AUTOSAR XML (schema 4-0-3)
standard types defined: Boolean, UInt32, UInt8
package /AUTOSAR_Platform/DataConstrs
  range DC_Boolean: raw 0..1
  range DC_UInt8: raw 0..255
package /PATAC/MSM/ComponentTypes
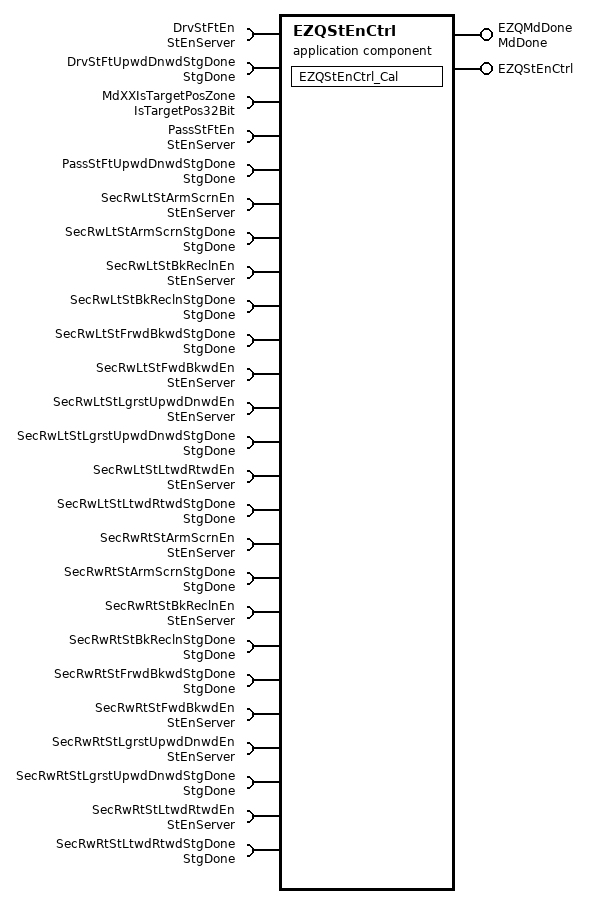
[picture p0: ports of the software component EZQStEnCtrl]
  application sw component type EZQStEnCtrl
    provide port EZQMdDone: nonqueued-sender-com-spec{data-element=MdDone/Val, init-value=0}, provided-interface=MdDone
    provide port EZQStEnCtrl: server-com-spec{operation=Cal, queue-length=1}, provided-interface=EZQStEnCtrl
    25 x require port:
      DrvStFtEn: required-com-specs=[Clear, Get, Set], required-interface=StEnServer
      DrvStFtUpwdDnwdStgDone: nonqueued-receiver-com-spec{data-element=StgDone/Val, filter=data-filter-type=ALWAYS, init-value=0}, required-interface=StgDone
      MdXXIsTargetPosZone: nonqueued-receiver-com-spec{data-element=IsTargetPos32Bit/Val, filter=data-filter-type=ALWAYS, init-value=0}, required-interface=IsTargetPos32Bit
      PassStFtEn: required-com-specs=[Clear, Get, Set], required-interface=StEnServer
      PassStFtUpwdDnwdStgDone: nonqueued-receiver-com-spec{data-element=StgDone/Val, filter=data-filter-type=ALWAYS, init-value=0}, required-interface=StgDone
      SecRwLtStArmScrnEn: required-com-specs=[Clear, Get, Set], required-interface=StEnServer
      SecRwLtStArmScrnStgDone: nonqueued-receiver-com-spec{data-element=StgDone/Val, filter=data-filter-type=ALWAYS, init-value=0}, required-interface=StgDone
      SecRwLtStBkReclnEn: required-com-specs=[Clear, Get, Set], required-interface=StEnServer
      SecRwLtStBkReclnStgDone: nonqueued-receiver-com-spec{data-element=StgDone/Val, filter=data-filter-type=ALWAYS, init-value=0}, required-interface=StgDone
      SecRwLtStFrwdBkwdStgDone: nonqueued-receiver-com-spec{data-element=StgDone/Val, filter=data-filter-type=ALWAYS, init-value=0}, required-interface=StgDone
      SecRwLtStFwdBkwdEn: required-com-specs=[Clear, Get, Set], required-interface=StEnServer
      SecRwLtStLgrstUpwdDnwdEn: required-com-specs=[Clear, Get, Set], required-interface=StEnServer
      SecRwLtStLgrstUpwdDnwdStgDone: nonqueued-receiver-com-spec{data-element=StgDone/Val, filter=data-filter-type=ALWAYS, init-value=0}, required-interface=StgDone
      SecRwLtStLtwdRtwdEn: required-com-specs=[Clear, Get, Set], required-interface=StEnServer
      SecRwLtStLtwdRtwdStgDone: nonqueued-receiver-com-spec{data-element=StgDone/Val, filter=data-filter-type=ALWAYS, init-value=0}, required-interface=StgDone
      SecRwRtStArmScrnEn: required-com-specs=[Clear, Get, Set], required-interface=StEnServer
      SecRwRtStArmScrnStgDone: nonqueued-receiver-com-spec{data-element=StgDone/Val, filter=data-filter-type=ALWAYS, init-value=0}, required-interface=StgDone
      SecRwRtStBkReclnEn: required-com-specs=[Clear, Get, Set], required-interface=StEnServer
      SecRwRtStBkReclnStgDone: nonqueued-receiver-com-spec{data-element=StgDone/Val, filter=data-filter-type=ALWAYS, init-value=0}, required-interface=StgDone
      SecRwRtStFrwdBkwdStgDone: nonqueued-receiver-com-spec{data-element=StgDone/Val, filter=data-filter-type=ALWAYS, init-value=0}, required-interface=StgDone
      SecRwRtStFwdBkwdEn: required-com-specs=[Clear, Get, Set], required-interface=StEnServer
      SecRwRtStLgrstUpwdDnwdEn: required-com-specs=[Clear, Get, Set], required-interface=StEnServer
      SecRwRtStLgrstUpwdDnwdStgDone: nonqueued-receiver-com-spec{data-element=StgDone/Val, filter=data-filter-type=ALWAYS, init-value=0}, required-interface=StgDone
      SecRwRtStLtwdRtwdEn: required-com-specs=[Clear, Get, Set], required-interface=StEnServer
      SecRwRtStLtwdRtwdStgDone: nonqueued-receiver-com-spec{data-element=StgDone/Val, filter=data-filter-type=ALWAYS, init-value=0}, required-interface=StgDone
    behavior EZQStEnCtrl_InternalBehavior
      operation invoked event OIT_EZQStEnCtrl_Cal_EZQStEnCtrl_Cal: start-on-event=EZQStEnCtrl_Cal, operation=EZQStEnCtrl.Cal
      runnable EZQStEnCtrl_Cal
        data-receive-point-by-arguments:
          13 x access:
            REC_DrvStFtUpwdDnwdStgDone_Val: accessed-variable=DrvStFtUpwdDnwdStgDone.Val
            REC_MdXXIsTargetPosZone_Val: accessed-variable=MdXXIsTargetPosZone.Val
            REC_PassStFtUpwdDnwdStgDone_Val: accessed-variable=PassStFtUpwdDnwdStgDone.Val
            REC_SecRwLtStArmScrnStgDone_Val: accessed-variable=SecRwLtStArmScrnStgDone.Val
            REC_SecRwLtStBkReclnStgDone_Val: accessed-variable=SecRwLtStBkReclnStgDone.Val
            REC_SecRwLtStFrwdBkwdStgDone_Val: accessed-variable=SecRwLtStFrwdBkwdStgDone.Val
            REC_SecRwLtStLgrstUpwdDnwdStgDone_Val: accessed-variable=SecRwLtStLgrstUpwdDnwdStgDone.Val
            REC_SecRwLtStLtwdRtwdStgDone_Val: accessed-variable=SecRwLtStLtwdRtwdStgDone.Val
            REC_SecRwRtStArmScrnStgDone_Val: accessed-variable=SecRwRtStArmScrnStgDone.Val
            REC_SecRwRtStBkReclnStgDone_Val: accessed-variable=SecRwRtStBkReclnStgDone.Val
            REC_SecRwRtStFrwdBkwdStgDone_Val: accessed-variable=SecRwRtStFrwdBkwdStgDone.Val
            REC_SecRwRtStLgrstUpwdDnwdStgDone_Val: accessed-variable=SecRwRtStLgrstUpwdDnwdStgDone.Val
            REC_SecRwRtStLtwdRtwdStgDone_Val: accessed-variable=SecRwRtStLtwdRtwdStgDone.Val
        data-send-points:
          access SEND_EZQMdDone_Val: accessed-variable=EZQMdDone.Val
        24 x sync call, all with timeout=0:
          SC_DrvStFtEn_Clear: operation=DrvStFtEn.Clear
          SC_DrvStFtEn_Set: operation=DrvStFtEn.Set
          SC_PassStFtEn_Clear: operation=PassStFtEn.Clear
          SC_PassStFtEn_Set: operation=PassStFtEn.Set
          SC_SecRwLtStArmScrnEn_Clear: operation=SecRwLtStArmScrnEn.Clear
          SC_SecRwLtStArmScrnEn_Set: operation=SecRwLtStArmScrnEn.Set
          SC_SecRwLtStBkReclnEn_Clear: operation=SecRwLtStBkReclnEn.Clear
          SC_SecRwLtStBkReclnEn_Set: operation=SecRwLtStBkReclnEn.Set
          SC_SecRwLtStFwdBkwdEn_Clear: operation=SecRwLtStFwdBkwdEn.Clear
          SC_SecRwLtStFwdBkwdEn_Set: operation=SecRwLtStFwdBkwdEn.Set
          SC_SecRwLtStLgrstUpwdDnwdEn_Clear: operation=SecRwLtStLgrstUpwdDnwdEn.Clear
          SC_SecRwLtStLgrstUpwdDnwdEn_Set: operation=SecRwLtStLgrstUpwdDnwdEn.Set
          SC_SecRwLtStLtwdRtwdEn_Clear: operation=SecRwLtStLtwdRtwdEn.Clear
          SC_SecRwLtStLtwdRtwdEn_Set: operation=SecRwLtStLtwdRtwdEn.Set
          SC_SecRwRtStArmScrnEn_Clear: operation=SecRwRtStArmScrnEn.Clear
          SC_SecRwRtStArmScrnEn_Set: operation=SecRwRtStArmScrnEn.Set
          SC_SecRwRtStBkReclnEn_Clear: operation=SecRwRtStBkReclnEn.Clear
          SC_SecRwRtStBkReclnEn_Set: operation=SecRwRtStBkReclnEn.Set
          SC_SecRwRtStFwdBkwdEn_Clear: operation=SecRwRtStFwdBkwdEn.Clear
          SC_SecRwRtStFwdBkwdEn_Set: operation=SecRwRtStFwdBkwdEn.Set
          SC_SecRwRtStLgrstUpwdDnwdEn_Clear: operation=SecRwRtStLgrstUpwdDnwdEn.Clear
          SC_SecRwRtStLgrstUpwdDnwdEn_Set: operation=SecRwRtStLgrstUpwdDnwdEn.Set
          SC_SecRwRtStLtwdRtwdEn_Clear: operation=SecRwRtStLtwdRtwdEn.Clear
          SC_SecRwRtStLtwdRtwdEn_Set: operation=SecRwRtStLtwdRtwdEn.Set
  swc implementation EZQStEnCtrl_Implementation: behavior=EZQStEnCtrl_InternalBehavior
    code-descriptors:
      code Default: artifact-descriptors=autosar-engineering-object={short-label=Default, category=SWSRC}
package /PATAC/MSM/ModeAdjust/PortInterface
  client server interface EZQStEnCtrl
    operation Cal
  client server interface StEnServer
    operation Clear
      arg data: type=UInt8, direction=IN, server-argument-impl-policy=USE-ARGUMENT-TYPE
    operation Get
      arg data: type=UInt32, direction=OUT, server-argument-impl-policy=USE-ARGUMENT-TYPE
    operation Set
      arg data: type=UInt8, direction=IN, server-argument-impl-policy=USE-ARGUMENT-TYPE
  sender receiver interface IsTargetPos32Bit: invalidation-policy{data-element=IsTargetPos32Bit/Val, handle-invalid=DONT-INVALIDATE}
    data Val: type=UInt32
  sender receiver interface MdDone: invalidation-policy{data-element=MdDone/Val, handle-invalid=DONT-INVALIDATE}
    data Val: type=UInt8
  sender receiver interface StgDone: invalidation-policy{data-element=StgDone/Val, handle-invalid=DONT-INVALIDATE}
    data Val: type=Boolean
